# A31R71x register map
Vendor: VENDOR ABOV Semiconductor Co., Ltd.; Series: A31R71x; File version: 1.0
CPU: CM0+ r0p1, little endian, no MPU, no FPU, VTOR, 2 interrupt priority bits
Registers are 32-bit, read-write, reset 0x0 unless marked. A register's access mark holds for its fields unless they carry their own. Offsets are from the block's base; [hi:lo] are bit positions; {n}, {i} and the like mark numbered series; 'fields as' and 'values as' point back to an identical list.

## INTC — Interrupt Controller
Base 0x40001000
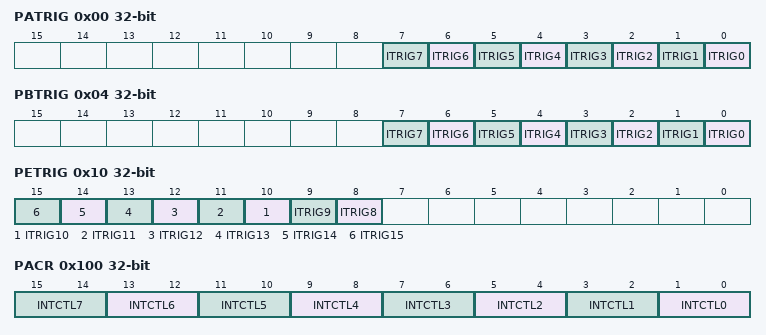
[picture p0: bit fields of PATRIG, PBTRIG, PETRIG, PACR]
0x00 PATRIG — Port A Interrupt Trigger Selection Register
  [all] fields
    0=Edge trigger interrupt; 1=Level trigger interrupt
  [n] ITRIG{n} (n=0..7) — Port A Interrupt Trigger Selection {n}
0x04 PBTRIG — Port B Interrupt Trigger Selection Register
  [all] fields
    0=Edge trigger interrupt; 1=Level trigger interrupt
  [n] ITRIG{n} (n=0..7) — Port B Interrupt Trigger Selection {n}
0x10 PETRIG — Port E Interrupt Trigger Selection Register
  [all] fields
    0=Edge trigger interrupt; 1=Level trigger interrupt
  [n] ITRIG{n} (n=8..15) — Port E Interrupt Trigger Selection {n}
0x100 PACR — Port A Interrupt Control Register
  [all] fields
    0=Disable external interrupt; 1=FallingEdgeLowLevel (Interrupt on falling edge or on low level); 2=RisingEdgeHighLevel (Interrupt on rising edge or on high level); 3=BothEdgeNoLevel (Interrupt on both falling and rising edge, No level interrupt)
  [2n+1:2n] INTCTL{n} (n=0..7) — Port A Interrupt Control {n}
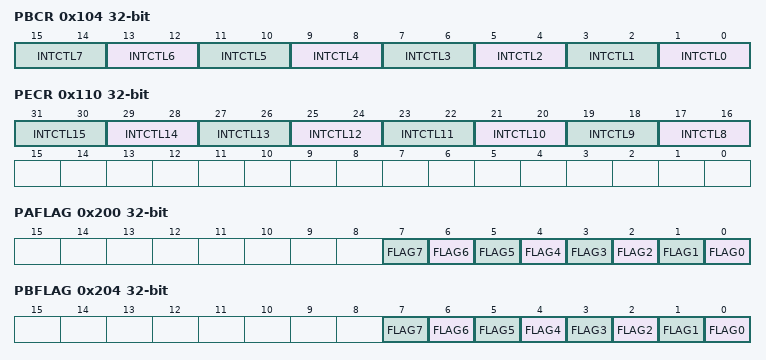
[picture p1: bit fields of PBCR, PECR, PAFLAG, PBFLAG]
0x104 PBCR — Port B Interrupt Control Register
  [all] fields
    values as the fields of PACR
  [2n+1:2n] INTCTL{n} (n=0..7) — Port B Interrupt Control {n}
0x110 PECR — Port E Interrupt Control Register
  [all] fields
    values as the fields of PACR
  [2n+1:2n] INTCTL{n} (n=8..15) — Port E Interrupt Control {n}
0x200 PAFLAG — Port A Interrupt Flag Register
  [all] fields
    0=No request occurred; 1=Request occurred
  [n] FLAG{n} (n=0..7) — Port A Interrupt Flag {n}
0x204 PBFLAG — Port B Interrupt Flag Register
  [all] fields
    0=No request occurred; 1=Request occurred
  [n] FLAG{n} (n=0..7) — Port B Interrupt Flag {n}
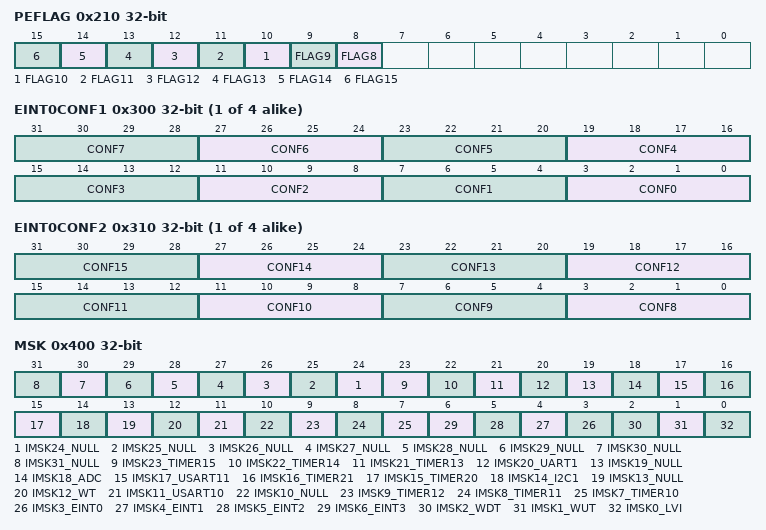
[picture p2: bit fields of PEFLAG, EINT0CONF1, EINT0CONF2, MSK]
0x210 PEFLAG — Port E Interrupt Flag Register
  [all] fields
    0=No request occurred; 1=Request occurred
  [n] FLAG{n} (n=8..15) — Port E Interrupt Flag {n}
{0x300+4i} EINT{i}CONF1 (i=0..3) — External Interrupt {i} Configuration Register 1
  [all] fields
    0=PA (Select PA.); 1=PB (Select PB.); 2=PC (Select PC.); 3=PD (Select PD.); 4=PE (Select PE.); 5=PF (Select PF.)
  [4n+3:4n] CONF{n} (n=0..7) — External Interrupt {i} Configuration {n}
{0x310+4i} EINT{i}CONF2 (i=0..3) — External Interrupt {i} Configuration Register 2
  [all] fields
    values as the fields of EINT0CONF1
  [4n-29:4n-32] CONF{n} (n=8..15) — External Interrupt {i} Configuration {n}
0x400 MSK — Interrupt Source Mask Register
  [all] fields
    0=Mask Interrupt Source; 1=Unmask Interrupt Source
  [n] IMSK{n}_NULL (n=24..31) — Interrupt Source Mask {n} (RSVD)
  [23] IMSK23_TIMER15 — Interrupt Source Mask 23 (TIMER15)
  [22] IMSK22_TIMER14 — Interrupt Source Mask 22 (TIMER14)
  [21] IMSK21_TIMER13 — Interrupt Source Mask 21 (TIMER13)
  [20] IMSK20_UART1 — Interrupt Source Mask 20 (UART1)
  [19] IMSK19_NULL — Interrupt Source Mask 19 (RSVD)
  [18] IMSK18_ADC — Interrupt Source Mask 18 (ADC)
  [17] IMSK17_USART11 — Interrupt Source Mask 17 (USART11)
  [16] IMSK16_TIMER21 — Interrupt Source Mask 16 (TIMER21)
  [15] IMSK15_TIMER20 — Interrupt Source Mask 15 (TIMER20)
  [14] IMSK14_I2C1 — Interrupt Source Mask 14 (I2C1)
  [13] IMSK13_NULL — Interrupt Source Mask 13 (RSVD)
  [12] IMSK12_WT — Interrupt Source Mask 12 (WT)
  [11] IMSK11_USART10 — Interrupt Source Mask 11 (USART10)
  [10] IMSK10_NULL — Interrupt Source Mask 10 (RSVD)
  [9] IMSK9_TIMER12 — Interrupt Source Mask 9 (TIMER12)
  [8] IMSK8_TIMER11 — Interrupt Source Mask 8 (TIMER11)
  [7] IMSK7_TIMER10 — Interrupt Source Mask 7 (TIMER10)
  [n] IMSK{n}_EINT{n-3} (n=3..6) — Interrupt Source Mask {n} (EINT{n-3})
  [2] IMSK2_WDT — Interrupt Source Mask 2 (WDT)
  [1] IMSK1_WUT — Interrupt Source Mask 1 (WUT)
  [0] IMSK0_LVI — Interrupt Source Mask 0 (LVI)
